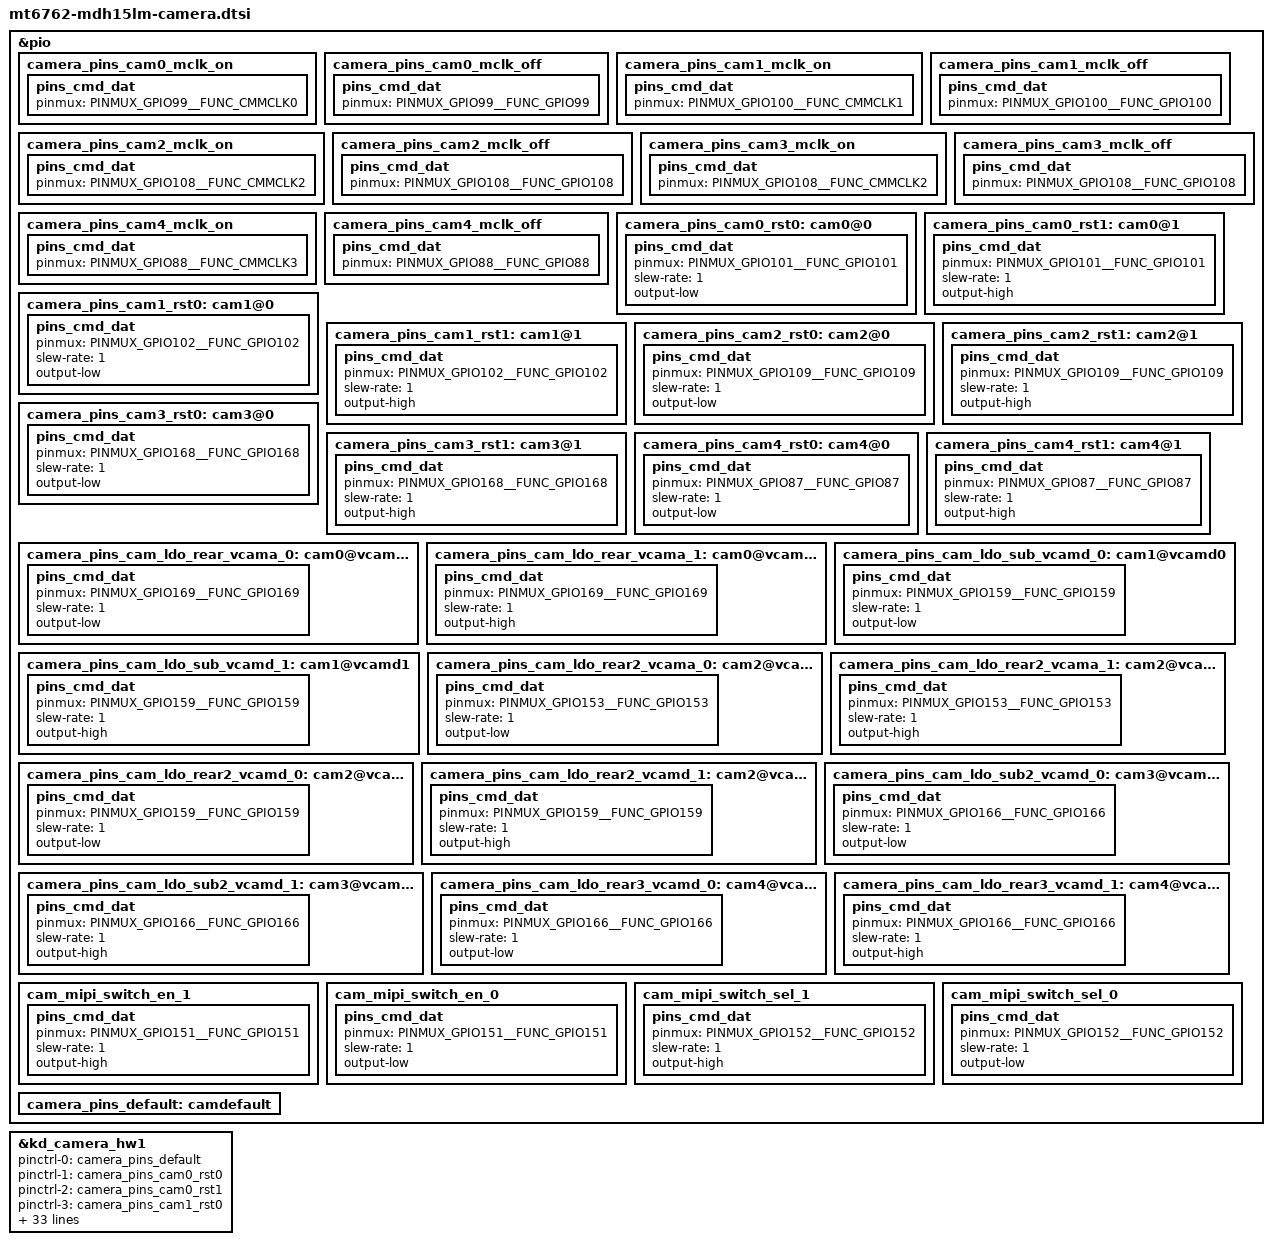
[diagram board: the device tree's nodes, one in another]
/*
 * LG Electronics MT6765 HDK camera device tree source
 *
 * Copyright (c) 2018 LG Electronics Co., Ltd.
 *              http://www.lge.com
 *
 */

&pio {
	camera_pins_cam0_mclk_on: camera_pins_cam0_mclk_on {
		pins_cmd_dat {
			pinmux = <PINMUX_GPIO99__FUNC_CMMCLK0>;
		};
	};
	camera_pins_cam0_mclk_off: camera_pins_cam0_mclk_off {
		pins_cmd_dat {
			pinmux = <PINMUX_GPIO99__FUNC_GPIO99>;
		};
	};
	camera_pins_cam1_mclk_on: camera_pins_cam1_mclk_on {
		pins_cmd_dat {
			pinmux = <PINMUX_GPIO100__FUNC_CMMCLK1>;
		};
	};
	camera_pins_cam1_mclk_off: camera_pins_cam1_mclk_off {
		pins_cmd_dat {
			pinmux = <PINMUX_GPIO100__FUNC_GPIO100>;
		};
	};
	camera_pins_cam2_mclk_on: camera_pins_cam2_mclk_on {
		pins_cmd_dat {
			pinmux = <PINMUX_GPIO108__FUNC_CMMCLK2>;
		};
	};
	camera_pins_cam2_mclk_off: camera_pins_cam2_mclk_off {
		pins_cmd_dat {
			pinmux = <PINMUX_GPIO108__FUNC_GPIO108>;
		};
	};
	camera_pins_cam3_mclk_on: camera_pins_cam3_mclk_on {//Modify for sub2 macro
		pins_cmd_dat {
			pinmux = <PINMUX_GPIO108__FUNC_CMMCLK2>;
		};
	};
	camera_pins_cam3_mclk_off: camera_pins_cam3_mclk_off {
		pins_cmd_dat {
			pinmux = <PINMUX_GPIO108__FUNC_GPIO108>;
		};
	};
	camera_pins_cam4_mclk_on: camera_pins_cam4_mclk_on {//Modify for main3 depth
		pins_cmd_dat {
			pinmux = <PINMUX_GPIO88__FUNC_CMMCLK3>;
		};
	};
	camera_pins_cam4_mclk_off: camera_pins_cam4_mclk_off {
		pins_cmd_dat {
			pinmux = <PINMUX_GPIO88__FUNC_GPIO88>;
		};
	};
	camera_pins_cam0_rst0: cam0@0 {
		pins_cmd_dat {
			pinmux = <PINMUX_GPIO101__FUNC_GPIO101>;
			slew-rate = <1>;
			output-low;
		};
	};
	camera_pins_cam0_rst1: cam0@1 {
		pins_cmd_dat {
			pinmux = <PINMUX_GPIO101__FUNC_GPIO101>;
			slew-rate = <1>;
			output-high;
		};
	};
	camera_pins_cam1_rst0: cam1@0 {
		pins_cmd_dat {
			pinmux = <PINMUX_GPIO102__FUNC_GPIO102>;
			slew-rate = <1>;
			output-low;
		};
	};
	camera_pins_cam1_rst1: cam1@1 {
		pins_cmd_dat {
			pinmux = <PINMUX_GPIO102__FUNC_GPIO102>;
			slew-rate = <1>;
			output-high;
		};
	};
	camera_pins_cam2_rst0: cam2@0 {// rear guangjiao 5M hi556
		pins_cmd_dat {
			pinmux = <PINMUX_GPIO109__FUNC_GPIO109>;
			slew-rate = <1>;
			output-low;
		};
	};
	camera_pins_cam2_rst1: cam2@1 {
		pins_cmd_dat {
			pinmux = <PINMUX_GPIO109__FUNC_GPIO109>;
			slew-rate = <1>;
			output-high;
		};
	};
	camera_pins_cam3_rst0: cam3@0 { //sub2 macro reset
		pins_cmd_dat {
			pinmux = <PINMUX_GPIO168__FUNC_GPIO168>;
			slew-rate = <1>;
			output-low;
		};
	};
	camera_pins_cam3_rst1: cam3@1 {
		pins_cmd_dat {
			pinmux = <PINMUX_GPIO168__FUNC_GPIO168>;
			slew-rate = <1>;
			output-high;
		};
	};
	camera_pins_cam4_rst0: cam4@0 {//main3 depth reset
		pins_cmd_dat {
			pinmux = <PINMUX_GPIO87__FUNC_GPIO87>;
			slew-rate = <1>;
			output-low;
		};
	};
	camera_pins_cam4_rst1: cam4@1 {
		pins_cmd_dat {
			pinmux = <PINMUX_GPIO87__FUNC_GPIO87>;
			slew-rate = <1>;
			output-high;
		};
	};
	camera_pins_cam_ldo_rear_vcama_0: cam0@vcama0 {
		pins_cmd_dat {
			pinmux = <PINMUX_GPIO169__FUNC_GPIO169>;
			slew-rate = <1>;
			output-low;
		};
	};
	camera_pins_cam_ldo_rear_vcama_1: cam0@vcama1 {
		pins_cmd_dat {
			pinmux = <PINMUX_GPIO169__FUNC_GPIO169>;
			slew-rate = <1>;
			output-high;
		};
	};
	camera_pins_cam_ldo_sub_vcamd_0: cam1@vcamd0 {
		pins_cmd_dat {
			pinmux = <PINMUX_GPIO159__FUNC_GPIO159>;
			slew-rate = <1>;
			output-low;
		};
	};
	camera_pins_cam_ldo_sub_vcamd_1: cam1@vcamd1 {
		pins_cmd_dat {
			pinmux = <PINMUX_GPIO159__FUNC_GPIO159>;
			slew-rate = <1>;
			output-high;
		};
	};
	camera_pins_cam_ldo_rear2_vcama_0: cam2@vcama0 {
		pins_cmd_dat {
			pinmux = <PINMUX_GPIO153__FUNC_GPIO153>;
			slew-rate = <1>;
			output-low;
		};
	};
	camera_pins_cam_ldo_rear2_vcama_1: cam2@vcama1 {
		pins_cmd_dat {
			pinmux = <PINMUX_GPIO153__FUNC_GPIO153>;
			slew-rate = <1>;
			output-high;
		};
	};

	camera_pins_cam_ldo_rear2_vcamd_0: cam2@vcamd0 {//M510 add hi556 vdd
		pins_cmd_dat {
			pinmux = <PINMUX_GPIO159__FUNC_GPIO159>;
			slew-rate = <1>;
			output-low;
		};
	};
	camera_pins_cam_ldo_rear2_vcamd_1: cam2@vcamd1 {
		pins_cmd_dat {
			pinmux = <PINMUX_GPIO159__FUNC_GPIO159>;
			slew-rate = <1>;
			output-high;
		};
	};

       camera_pins_cam_ldo_sub2_vcamd_0: cam3@vcamd0 {//Modify for sub2 macro
		pins_cmd_dat {
			pinmux = <PINMUX_GPIO166__FUNC_GPIO166>;
			slew-rate = <1>;
			output-low;
		};
	};
	camera_pins_cam_ldo_sub2_vcamd_1: cam3@vcamd1 {
		pins_cmd_dat {
			pinmux = <PINMUX_GPIO166__FUNC_GPIO166>;
			slew-rate = <1>;
			output-high;
		};
	};
	camera_pins_cam_ldo_rear3_vcamd_0: cam4@vcamd0 {//Modify for main3 depth
		pins_cmd_dat {
			pinmux = <PINMUX_GPIO166__FUNC_GPIO166>;
			slew-rate = <1>;
			output-low;
		};
	};
	camera_pins_cam_ldo_rear3_vcamd_1: cam4@vcamd1 {
		pins_cmd_dat {
			pinmux = <PINMUX_GPIO166__FUNC_GPIO166>;
			slew-rate = <1>;
			output-high;
		};
	};
	
	cam_mipi_switch_en_1: cam_mipi_switch_en_1 {//M510 mipi switch
		pins_cmd_dat {
			pinmux = <PINMUX_GPIO151__FUNC_GPIO151>;
			slew-rate = <1>;
                        output-high;
		};
	};

	cam_mipi_switch_en_0: cam_mipi_switch_en_0 {
		pins_cmd_dat {
			pinmux = <PINMUX_GPIO151__FUNC_GPIO151>;
			slew-rate = <1>;
                        output-low;
		};
	};

	cam_mipi_switch_sel_1: cam_mipi_switch_sel_1 {
		pins_cmd_dat {
			pinmux = <PINMUX_GPIO152__FUNC_GPIO152>;
			slew-rate = <1>;
                        output-high;
		};
	};

	cam_mipi_switch_sel_0: cam_mipi_switch_sel_0 {
		pins_cmd_dat {
			pinmux = <PINMUX_GPIO152__FUNC_GPIO152>;
			slew-rate = <1>;
                        output-low;
		};
	};

	camera_pins_default: camdefault {
	};

};

&kd_camera_hw1 {
	pinctrl-names = "default",
			"cam0_rst0",
			"cam0_rst1",
			"cam1_rst0",
			"cam1_rst1",
			"cam2_rst0",
			"cam2_rst1",
			"cam3_rst0",
			"cam3_rst1",
			"cam4_rst0",
			"cam4_rst1",
			"cam0_vcama_on",
			"cam0_vcama_off",
			"cam1_vcamd_on",
			"cam1_vcamd_off",
			"cam2_vcama_on",
			"cam2_vcama_off",
                     "cam2_vcamd_on",
                     "cam2_vcamd_off",
                     "cam3_vcamd_on",
                     "cam3_vcamd_off",
                     "cam4_vcamd_on",
                     "cam4_vcamd_off",
			"cam0_mclk_on",
			"cam0_mclk_off",
			"cam1_mclk_on",
			"cam1_mclk_off",
			"cam2_mclk_on",
			"cam2_mclk_off",
			"cam3_mclk_on",
			"cam3_mclk_off",
			"cam4_mclk_on",
			"cam4_mclk_off",
                     "cam_mipi_switch_en_1",
                     "cam_mipi_switch_en_0",
                     "cam_mipi_switch_sel_1",
                     "cam_mipi_switch_sel_0";

	pinctrl-0 = <&camera_pins_default>;
	pinctrl-1 = <&camera_pins_cam0_rst0>;
	pinctrl-2 = <&camera_pins_cam0_rst1>;
	pinctrl-3 = <&camera_pins_cam1_rst0>;
	pinctrl-4 = <&camera_pins_cam1_rst1>;
	pinctrl-5 = <&camera_pins_cam2_rst0>;
	pinctrl-6 = <&camera_pins_cam2_rst1>;
	pinctrl-7 = <&camera_pins_cam3_rst0>;
	pinctrl-8 = <&camera_pins_cam3_rst1>;
	pinctrl-9 = <&camera_pins_cam4_rst0>;
	pinctrl-10 = <&camera_pins_cam4_rst1>;
	pinctrl-11 = <&camera_pins_cam_ldo_rear_vcama_1>;
	pinctrl-12 = <&camera_pins_cam_ldo_rear_vcama_0>;
	pinctrl-13 = <&camera_pins_cam_ldo_sub_vcamd_1>;
	pinctrl-14 = <&camera_pins_cam_ldo_sub_vcamd_0>;
	pinctrl-15 = <&camera_pins_cam_ldo_rear2_vcama_1>;
	pinctrl-16 = <&camera_pins_cam_ldo_rear2_vcama_0>; 
	pinctrl-17 = <&camera_pins_cam_ldo_rear2_vcamd_1>;//M510 hi556 add
	pinctrl-18 = <&camera_pins_cam_ldo_rear2_vcamd_0>;
	pinctrl-19 = <&camera_pins_cam_ldo_sub2_vcamd_1>;
	pinctrl-20 = <&camera_pins_cam_ldo_sub2_vcamd_0>;
	pinctrl-21 = <&camera_pins_cam_ldo_rear3_vcamd_1>;
	pinctrl-22 = <&camera_pins_cam_ldo_rear3_vcamd_0>;
	pinctrl-23 = <&camera_pins_cam0_mclk_on>;
	pinctrl-24 = <&camera_pins_cam0_mclk_off>;
	pinctrl-25 = <&camera_pins_cam1_mclk_on>;
	pinctrl-26 = <&camera_pins_cam1_mclk_off>;
	pinctrl-27 = <&camera_pins_cam2_mclk_on>;
	pinctrl-28 = <&camera_pins_cam2_mclk_off>;
	pinctrl-29 = <&camera_pins_cam3_mclk_on>;
	pinctrl-30 = <&camera_pins_cam3_mclk_off>;
	pinctrl-31 = <&camera_pins_cam4_mclk_on>;
	pinctrl-32 = <&camera_pins_cam4_mclk_off>;
	pinctrl-33 = <&cam_mipi_switch_en_1>;//M510 hi846 add
	pinctrl-34 = <&cam_mipi_switch_en_0>;
	pinctrl-35 = <&cam_mipi_switch_sel_1>;
	pinctrl-36 = <&cam_mipi_switch_sel_0>;
	status = "okay";
};

